# MCAN_ECC_52700000h register map
Vendor: Texas Instruments
Peripheral module from a debugger description file (folder AM263P).
Registers are 32-bit, read-write, reset 0x0 unless marked. A register's access mark holds for its fields unless they carry their own. Offsets are as the file gives them; lines under a group give offsets from that group; [hi:lo] are bit positions; {n}, {i} and the like mark numbered series; 'fields as' and 'values as' point back to an identical list; <NAME> marks a mode.

## ECC
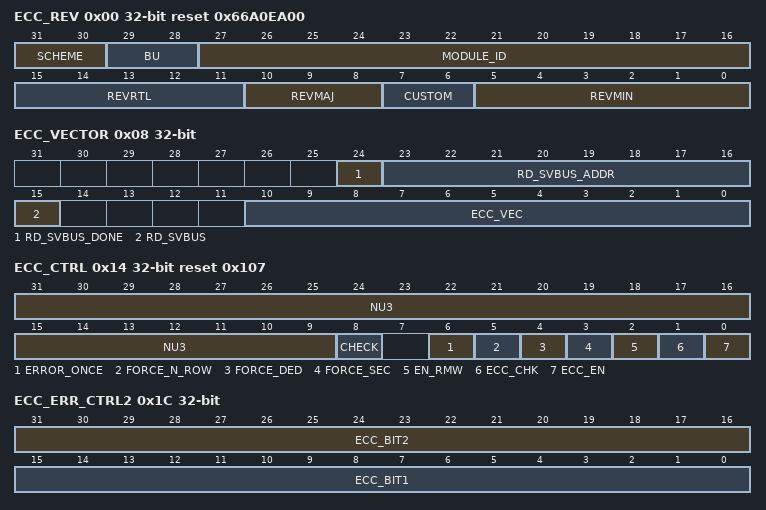
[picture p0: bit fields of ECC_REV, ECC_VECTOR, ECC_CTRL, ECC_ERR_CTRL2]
0x00 ECC_REV ro reset 0x66A0EA00 — Aggregator Revision Register. The Aggregator Revision Register contains the revision parameters for the ECC Aggregator.
  [31:30] SCHEME
  [29:28] BU — Business Unit
  [27:16] MODULE_ID
  [15:11] REVRTL — RTL version
  [10:8] REVMAJ — Major version
  [7:6] CUSTOM — Custom version
  [5:0] REVMIN — Minor version
0x08 ECC_VECTOR — ECC RAM ID to select which ECC RAM to control or read status from.
  [24] RD_SVBUS_DONE — Status to indicate if read on serial VBUS is complete, write of any value will clear this bit. Writing 1 to any bit will clear the corresponding bits. Reads do not alter the value of the field.
  [23:16] RD_SVBUS_ADDR — Read address
  [15] RD_SVBUS — Write 1 to trigger a read on the serial VBUS. Writing 1 to any bit will set the corresponding bit. Reads do not alter the value of the field.
  [10:0] ECC_VEC — Value written to select the corresponding ECC RAM for control or status
0x0C ECC_STAT ro reset 0x2 — Contains misc status such as number of ECC RAMs serviced by the ECC aggregator.
  [10:0] NUM_RAMS — Indicates the number of RAMS serviced by the ECC aggregator
0x14 ECC_CTRL access per field reset 0x107 — ECC Control Register.
  [31:9] NU3 ro — TI Internal : Reserved
  [8] CHECK rw — TI Internal : Check ParityTI Internal : Check timeout
  [6] ERROR_ONCE wo — TI Internal : Force Error only once
  [5] FORCE_N_ROW wo — TI Internal : Force Error on any RAM read
  [4] FORCE_DED wo — TI Internal : Force Double Bit Error
  [3] FORCE_SEC wo — TI Internal : Force Single Bit Error
  [2] EN_RMW wo — TI Internal : Enable rmw
  [1] ECC_CHK wo — TI Internal : Enable ECC check
  [0] ECC_EN wo — TI Internal : Enable ECC
0x18 ECC_ERR_CTRL1 — ECC Error Control1 Register.
  [31:0] ECC_ROW — TI Internal : Row address where single or double-bit error needs to be applied. This is ignored if force_n_row is set
0x1C ECC_ERR_CTRL2 — ECC Error Control2 Register.
  [31:16] ECC_BIT2 — TI Internal : Data bit that needs to be flipped if double bit error needs to be forced
  [15:0] ECC_BIT1 — TI Internal : Data bit that needs to be flipped when force_sec is set
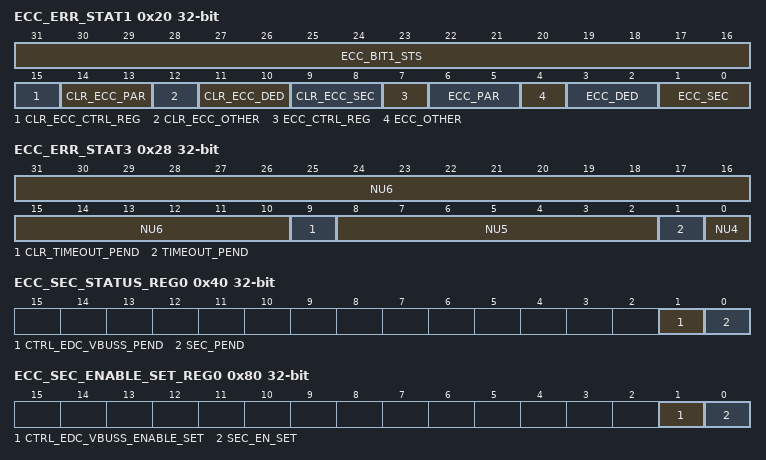
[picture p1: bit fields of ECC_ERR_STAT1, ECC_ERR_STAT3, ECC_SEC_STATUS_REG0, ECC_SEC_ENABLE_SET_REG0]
0x20 ECC_ERR_STAT1 access per field — ECC Error Status1 Register.
  [31:16] ECC_BIT1_STS ro — TI Internal : Data bit that corresponds to the single-bit error
  [15] CLR_ECC_CTRL_REG wo — TI Internal : Clear Ctrl Reg Error Status. Write 1 to clear. This bit is self clearing.
  [14:13] CLR_ECC_PAR wo — TI Internal : Clear Parity Error Status. Write 1 to clear. This bit is self clearing.
  [12] CLR_ECC_OTHER wo — TI Internal : Clear Other Error Status. Write 1 to clear. This bit is self clearing.
  [11:10] CLR_ECC_DED wo — TI Internal : Clear Double Bit Error Status. Write 1 to clear. This bit is self clearing.
  [9:8] CLR_ECC_SEC wo — TI Internal : Clear Single Bit Error Status. Write 1 to clear. This bit is self clearing.
  [7] ECC_CTRL_REG wo — TI Internal : Force ctrl reg pending interrupt. Write 1 to set. This bit is self clearing.
  [6:5] ECC_PAR wo — TI Internal : Force ECC parity pending interrupt. Write 1 to set. This bit is self clearing.
  [4] ECC_OTHER wo — TI Internal : Force ECC other pending interrupt. Write 1 to set. This bit is self clearing.
  [3:2] ECC_DED wo — TI Internal : Force ECC DED pending interrupt. Write 1 to set. This bit is self clearing.
  [1:0] ECC_SEC wo — TI Internal : Force ECC SEC pending interrupt. Write 1 to set. This bit is self clearing.
0x24 ECC_ERR_STAT2 ro — ECC Error Status2 Register.
  [31:0] ECC_ROW — TI Internal : Row address where the single or double-bit error has occurred
0x28 ECC_ERR_STAT3 access per field — ECC Error Status3 Register.
  [31:10] NU6 ro — TI Internal : Reserved
  [9] CLR_TIMEOUT_PEND wo — TI Internal : Clear timeout pending
  [8:2] NU5 ro — TI Internal : Reserved
  [1] TIMEOUT_PEND wo — TI Internal : Timeout pending
  [0] NU4 ro — TI Internal : Reserved
0x3C ECC_SEC_EOI_REG — EOI Register.
  [0] SEC_EOI_WR — EOI Register. Writing 1 to any bit will set the corresponding bit. Reads do not alter the value of the field. This bit is self clearing, Reading this bit will return 0.
0x40 ECC_SEC_STATUS_REG0 ro — Interrupt Status Register 0
  [1] CTRL_EDC_VBUSS_PEND — Interrupt Pending Status for ctrl_edc_vbuss_pend.
  [0] SEC_PEND — Interrupt Pending Status for msgmem_pend.
0x80 ECC_SEC_ENABLE_SET_REG0 — Interrupt Enable Set Register 0
  [1] CTRL_EDC_VBUSS_ENABLE_SET — Interrupt Enable Set Register for ctrl_edc_vbuss_pend. Writing 1 to any bit will set the corresponding bit. Reads do not alter the value of the field.
  [0] SEC_EN_SET — Interrupt Enable Set Register for msgmem_pend. Writing 1 to any bit will set the corresponding bit. Reads do not alter the value of the field.
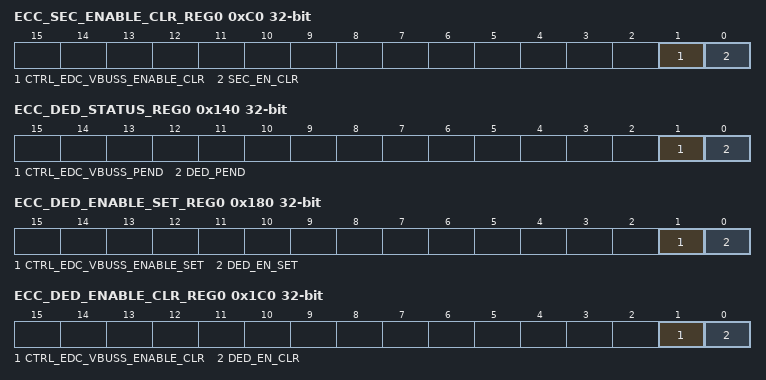
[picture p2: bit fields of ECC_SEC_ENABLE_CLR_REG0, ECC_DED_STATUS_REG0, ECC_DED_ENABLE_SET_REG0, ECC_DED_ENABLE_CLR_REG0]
0xC0 ECC_SEC_ENABLE_CLR_REG0 — Interrupt Enable Clear Register 0
  [1] CTRL_EDC_VBUSS_ENABLE_CLR — Interrupt Enable Clear Register for ctrl_edc_vbuss_pend. Writing 1 to any bit will clear the corresponding bits. Reads do not alter the value of the field. Reading this bit will return 0.
  [0] SEC_EN_CLR — Interrupt Enable Clear Register for msgmem_pend. Writing 1 to any bit will clear the corresponding bits. Reads do not alter the value of the field. Reading this bit will return 0.
0x13C ECC_DED_EOI_REG — EOI Register.
  [0] DED_EOI_WR — EOI Register. Writing 1 to any bit will set the corresponding bit. Reads do not alter the value of the field. This bit is self clearing, Reading this bit will return 0.
0x140 ECC_DED_STATUS_REG0 ro — Interrupt Status Register 0
  [1] CTRL_EDC_VBUSS_PEND — Interrupt Pending Status for ctrl_edc_vbuss_pend.
  [0] DED_PEND — Interrupt Pending Status for msgmem_pend.
0x180 ECC_DED_ENABLE_SET_REG0 — Interrupt Enable Set Register 0
  [1] CTRL_EDC_VBUSS_ENABLE_SET — Interrupt Enable Set Register for ctrl_edc_vbuss_pend. Writing 1 to any bit will set the corresponding bit. Reads do not alter the value of the field.
  [0] DED_EN_SET — Interrupt Enable Set Register for msgmem_pend. Writing 1 to any bit will set the corresponding bit. Reads do not alter the value of the field.
0x1C0 ECC_DED_ENABLE_CLR_REG0 — Interrupt Enable Clear Register 0
  [1] CTRL_EDC_VBUSS_ENABLE_CLR — Interrupt Enable Clear Register for ctrl_edc_vbuss_pend. Writing 1 to any bit will clear the corresponding bits. Reads do not alter the value of the field. Reading this bit will return 0.
  [0] DED_EN_CLR — Interrupt Enable Clear Register for msgmem_pend. Writing 1 to any bit will clear the corresponding bits. Reads do not alter the value of the field. Reading this bit will return 0.
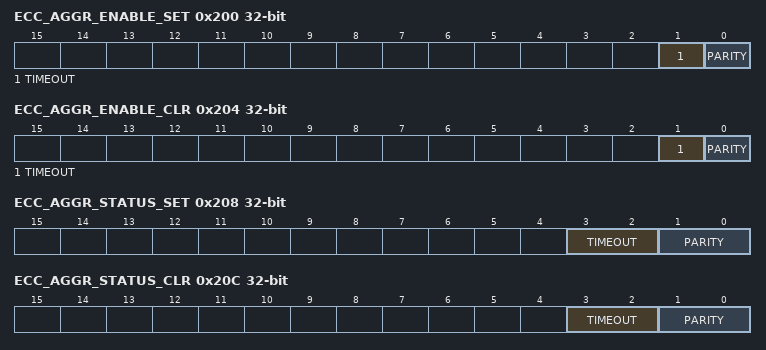
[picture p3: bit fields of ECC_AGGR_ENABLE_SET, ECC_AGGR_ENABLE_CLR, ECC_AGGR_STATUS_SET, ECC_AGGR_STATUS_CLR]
0x200 ECC_AGGR_ENABLE_SET — AGGR interrupt enable set Register.
  [1] TIMEOUT — Interrupt Enable Set Register for svbus timeout errors. Writing 1 to any bit will set the corresponding bit. Reads do not alter the value of the field.
  [0] PARITY — Interrupt Enable Set Register for parity errors. Writing 1 to any bit will set the corresponding bit. Reads do not alter the value of the field.
0x204 ECC_AGGR_ENABLE_CLR — AGGR interrupt enable clear Register.
  [1] TIMEOUT — Interrupt Enable Clear for svbus timeout errors. Writing 1 to any bit will clear the corresponding bits. Reads do not alter the value of the field. Reading this bit will return 0.
  [0] PARITY — Interrupt Enable Clear for parity errors. Writing 1 to any bit will clear the corresponding bits. Reads do not alter the value of the field. Reading this bit will return 0.
0x208 ECC_AGGR_STATUS_SET — AGGR interrupt status set Register.
  [3:2] TIMEOUT — 2-bit saturating counter of the number of timeout errors that have occurred since last cleared. 2'b00 - No timeout errors have occurred 2'b01 - 1 timeout erro has occurred 2'b10 - 2 timeout error has occurred 2'b11 - 3 or more timeout errors have occurred A write of a non-zero value to this register increments that many from the timeout fields. If the value written is less than the current value of the counter, then the pending level interrupt stays asserted. . If this register goes from 0 ot non zero a level interrupt will be asserted as well as a pulse interrupt. If the value was non zero to non zero then the level interrupt would remain asserted, but no new pulse interrupt would be asserted. You must write the eoi register to get a new pulse interrupt.
  [1:0] PARITY — 2-bit saturating counter of the number of parity errors that have occurred since last cleared. 2'b00 - No parity errors have occurred 2'b01 - 1 parity error has occurred 2'b10 - 2 parity error has occurred 2'b11 - 3 or more parity error have occurred A write of a non-zero value to this register incrments that many from the parity fields. If the value written is less than the current value of the counter, then the pending level interrupt stays asserted. If this register goes from 0 ot non zero a level interrupt will be asserted as well as a pulse interrupt. If the value was non zero to non zero then the level interrupt would remain asserted, but no new pulse interrupt would be asserted. You must write the eoi register to get a new pulse interrupt.
0x20C ECC_AGGR_STATUS_CLR — AGGR interrupt status clear Register.
  [3:2] TIMEOUT — 2'b00 - No timeout errors have occurred 2'b01 - 1 timeout erro has occurred 2'b10 - 2 timeout error has occurred 2'b11 - 3 or more timeout errors have occurred A write of a non-zero value to this register decrements that many from the timeout fields. If the resulting written value is non zero, then the pending level interrupt stays asserted. A new pulse interrupt will nto be asserted, you must write the eoi register for that to occur. If you write a value more than the counter value the result will be zero.
  [1:0] PARITY — 2'b00 - No parity errors have occurred 2'b01 - 1 parity error has occurred 2'b10 - 2 parity error has occurred 2'b11 - 3 or more parity error have occurred A write of a non-zero value to this register decrements that many from the parity fields. If the resulting written value is non zero, then the pending level interrupt stays asserted. A new pulse interrupt will nto be asserted, you must write the eoi register for that to occur. If you write a value more than the counter value the result will be zero.
